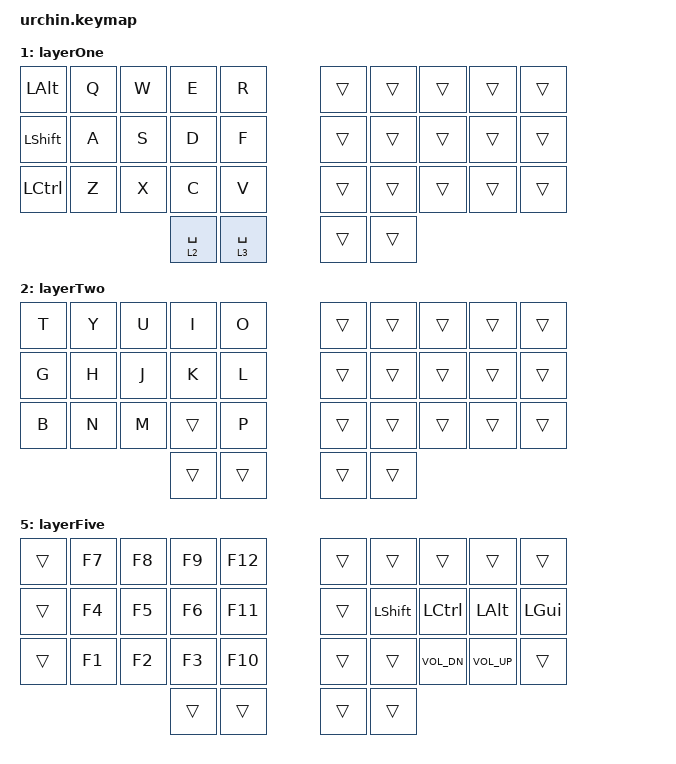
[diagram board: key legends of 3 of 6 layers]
#include <behaviors.dtsi>
#include <dt-bindings/zmk/keys.h>
#include <dt-bindings/zmk/bt.h>
#include <dt-bindings/zmk/outputs.h>

// -----------------

// Home row mods macro
#define HRML(k1,k2,k3,k4) &ht LGUI k1  &ht LALT k2  &ht LCTRL k3  &ht LSHFT k4
#define HRMR(k1,k2,k3,k4) &ht RSHFT k1  &ht RCTRL k2  &ht RALT k3  &ht RGUI k4

&sk {
	// don't release mods on other mods presses
	ignore-modifiers;
};

/ {
	behaviors {
		ht: hold_tap {
			compatible = "zmk,behavior-hold-tap";
			#binding-cells = <2>;
			flavor = "tap-preferred";
			tapping-term-ms = <220>;
			quick-tap-ms = <150>;
			global-quick-tap;
			bindings = <&kp>, <&kp>;
		};

		lt {
			tapping-term-ms = <200>;
			flavor = "tap-preferred";
			global-quick-tap;
		};
	};



	conditional_layers {
		compatible = "zmk,conditional-layers";
		layerThree {
		if-layers = <3 4>;
		then-layer = <5>;
		};
	};

	 combos {
        compatible = "zmk,combos";
        layerOne {
            timeout-ms = <50>;
            key-positions = <21 23>;
            bindings = <&tog 1>;
        };
    };

	keymap {
		compatible = "zmk,keymap";

		layerZero {
			bindings = <
			&kp Q      &kp W      &kp E      &kp R       &kp T           	&kp Y      &kp U      &kp I      &kp O      &kp P
			HRML(A,        S,         D,         F)      &kp G           	&kp H      HRMR(J,        K,     L,        SEMI)
			&kp Z      &kp X      &kp C      &kp V       &kp B           	&kp N      &kp M      &kp COMMA  &kp DOT    &kp APOS
							 			  &lt 3 TAB   &kp ENTER       		&kp SPACE  &lt 4 BSPC
			>;
		};

		layerOne {
			bindings = <
			&kp LALT   &kp Q &kp W &kp E &kp R        &trans &trans &trans &trans &trans   
			&kp LSHIFT &kp A &kp S &kp D &kp F        &trans &trans &trans &trans &trans    
			&kp LCTRL  &kp Z &kp X &kp C &kp V        &trans &trans &trans &trans &trans
					   &lt 2 SPACE &lt 3 SPACE        &trans &trans
			>;
		};

		layerTwo {
			bindings = <
			&kp T &kp Y &kp U &kp I &kp O        &trans &trans &trans &trans &trans   
			&kp G &kp H &kp J &kp K &kp L         &trans &trans &trans &trans &trans    
			&kp B &kp N &kp M &trans &kp P        &trans &trans &trans &trans &trans
							  &trans &trans      &trans &trans
			>;
		};

		layerThree {
			bindings = <
			&kp ESC     &kp N7     &kp N8    &kp N9    &kp INS  		  &trans  &kp HOME   &kp PG_DN  &kp PG_UP  &kp END    
			HRML(CAPS,     N4,        N5,       N6)    &kp DEL    		  &trans  &kp LARW   &kp DARW   &kp UARW   &kp RARW
			&kp TAB 	&kp N1      &kp N2   &kp N3    &kp N0         		  &trans  &trans     &trans     &trans     &trans
											 &trans    &trans             &trans  &trans
			>;
		};

	    layerFour {
			bindings = <
			&kp GRAVE    &kp LBKT   &kp LBRC   &kp RBRC   &kp DOLLAR    		 &kp CARET  &kp LPAR   &kp RPAR   &kp RBKT   &kp PERCENT
			HRML(STAR,       MINUS,     PLUS,      EQUAL) &kp TILDE     		 &trans    HRMR(AMPS,     PIPE,       EXCL,      QMARK)
			&kp HASH     &kp UNDER  &kp AT     &kp FSLH    &kp BSLH      		 &trans    &trans  	      &trans      &trans     &trans
							 						  &trans &trans       		 &trans    &trans
			>;
		};

		layerFive {
			bindings = <
			&trans      &kp F7     &kp F8     &kp F9    &kp F12        &trans     &trans 	   &trans 		&trans 		 &trans   
			&trans	    &kp F4     &kp F5     &kp F6    &kp F11        &trans     &kp LSHIFT   &kp LCTRL    &kp LALT     &kp LGUI    
			&trans 		&kp F1 	   &kp F2     &kp F3    &kp F10   	   &trans     &trans       &kp C_VOL_DN &kp C_VOL_UP &trans
							 				  &trans    &trans        &trans     &trans
			>;
		};
	};
};  
